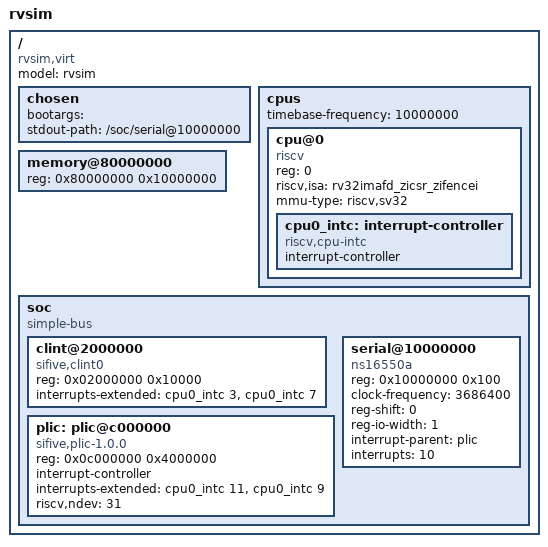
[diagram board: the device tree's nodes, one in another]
/dts-v1/;

/ {
    #address-cells = <1>;
    #size-cells = <1>;
    compatible = "rvsim,virt";
    model = "rvsim";

    chosen {
        bootargs = "";
        stdout-path = "/soc/serial@10000000";
    };

    cpus {
        #address-cells = <1>;
        #size-cells = <0>;
        /*
         * mtime ticks once per simulator cycle. 10 MHz is an arbitrary but
         * plausible figure that keeps OpenSBI's timer arithmetic sane during
         * boot. Adjust later if Linux complains about jiffies drift.
         */
        timebase-frequency = <10000000>;

        cpu@0 {
            device_type = "cpu";
            reg = <0>;
            status = "okay";
            compatible = "riscv";
            riscv,isa = "rv32imafd_zicsr_zifencei";
            mmu-type = "riscv,sv32";

            cpu0_intc: interrupt-controller {
                #interrupt-cells = <1>;
                interrupt-controller;
                compatible = "riscv,cpu-intc";
            };
        };
    };

    memory@80000000 {
        device_type = "memory";
        reg = <0x80000000 0x10000000>;   /* 256 MiB */
    };

    soc {
        #address-cells = <1>;
        #size-cells = <1>;
        compatible = "simple-bus";
        ranges;

        clint@2000000 {
            compatible = "sifive,clint0", "riscv,clint0";
            reg = <0x02000000 0x10000>;
            /* Per-hart MSI (3) and MTI (7) lines into the local INTC. */
            interrupts-extended = <&cpu0_intc 3 &cpu0_intc 7>;
        };

        plic: plic@c000000 {
            compatible = "sifive,plic-1.0.0", "riscv,plic0";
            reg = <0x0c000000 0x4000000>;
            #interrupt-cells = <1>;
            interrupt-controller;
            interrupts-extended = <&cpu0_intc 11 &cpu0_intc 9>;
            riscv,ndev = <31>;
        };

        serial@10000000 {
            compatible = "ns16550a";
            reg = <0x10000000 0x100>;
            clock-frequency = <3686400>;
            reg-shift = <0>;
            reg-io-width = <1>;
            interrupt-parent = <&plic>;
            interrupts = <10>;
        };
    };
};
